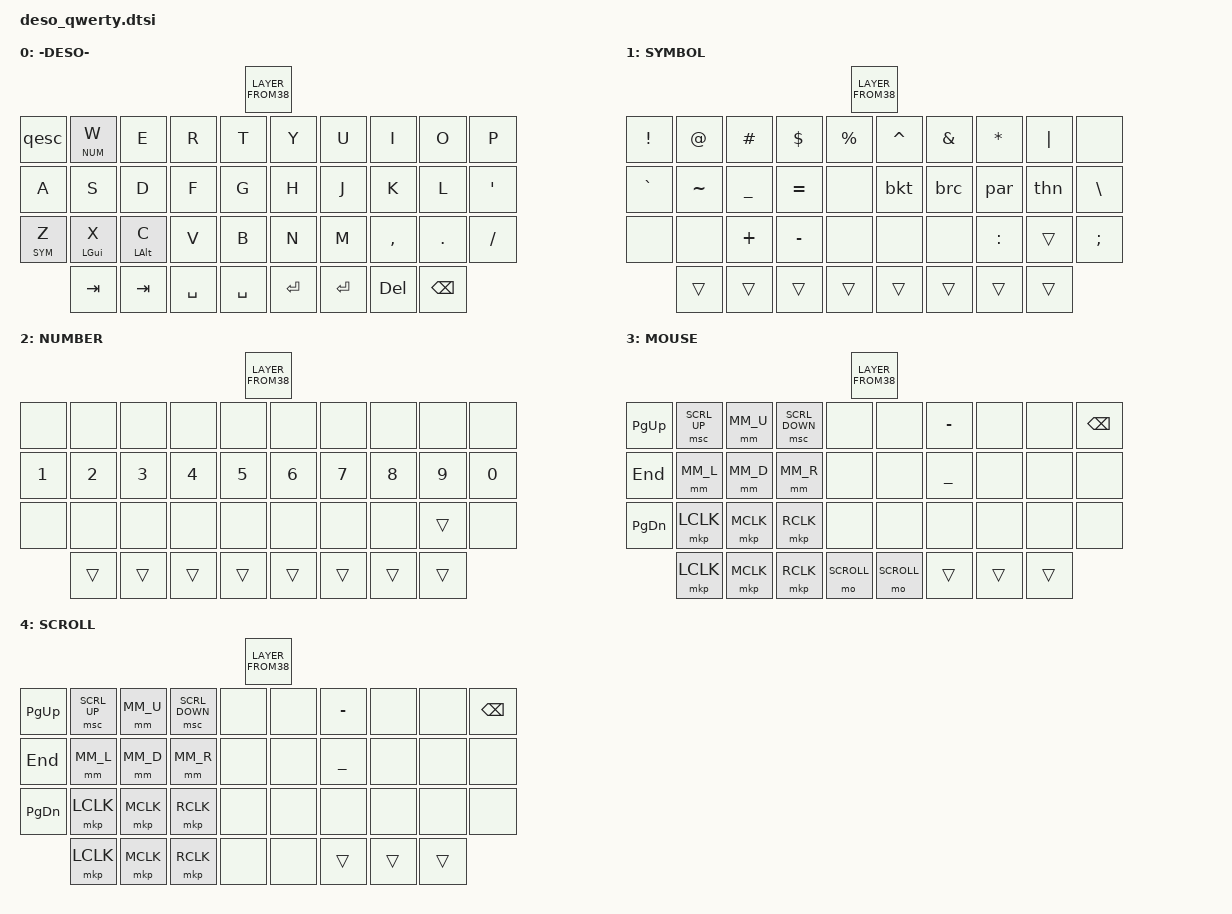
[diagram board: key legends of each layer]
/*
 * Last Update 10/5/24
 * QWERTY 19x2
 * 
 */

#include <behaviors.dtsi>
#include <input/processors.dtsi>
#include <dt-bindings/zmk/keys.h>
#include <dt-bindings/zmk/bt.h>
#include <dt-bindings/zmk/outputs.h>
#include <dt-bindings/zmk/mouse.h>
#include <dt-bindings/zmk/input_transform.h>
#include <zephyr/dt-bindings/input/input-event-codes.h>


#define DEFAULT     0
#define SYMBOL      1
#define NUMBER      2
#define MOUSE       3 
#define SCROLL      4

&mt {
    flavor = "tap-preferred";
    tapping_term_ms = <180>;
};

&lt {
    tapping_term_ms = <150>;
};

/ {
    combos {

        compatible = "zmk,combos";
        combo_bootloader {
            timeout-ms = <50>;
            key-positions = <1 10>;
            bindings = <&bootloader>;
        };
    };

    behaviors {

        qesc: tap_dance_qesc {
            compatible = "zmk,behavior-tap-dance";
            #binding-cells = <0>;
            tapping-term-ms = <300>;
            bindings = <&kp Q>, <&kp ESC>;
        };

        bkt: tap_dance_bracket {
            compatible = "zmk,behavior-tap-dance";
            #binding-cells = <0>;
            tapping-term-ms = <200>;
            bindings = <&kp LBKT>, <&kp RBKT>;
        };

        brc: tap_dance_brace {
            compatible = "zmk,behavior-tap-dance";
            #binding-cells = <0>;
            tapping-term-ms = <200>;
            bindings = <&kp LBRC>, <&kp RBRC>;
        };

        par: tap_dance_paren {
            compatible = "zmk,behavior-tap-dance";
            #binding-cells = <0>;
            tapping-term-ms = <200>;
            bindings = <&kp LPAR>, <&kp RPAR>;
        };

        thn: tap_dance_then {
            compatible = "zmk,behavior-tap-dance";
            #binding-cells = <0>;
            tapping-term-ms = <200>;
            bindings = <&kp LT>, <&kp GT>;
        };

        hrm: homerow_mods {
           compatible = "zmk,behavior-hold-tap";
           #binding-cells = <2>;
           tapping-term-ms = <250>;
           quick-tap-ms = <0>;
           flavor = "tap-preferred";
           bindings = <&kp>, <&kp>;
        };

        // keys to a fake mouse input device
        mm: mouse_move {
            compatible = "zmk,behavior-input-two-axis";
            #binding-cells = <1>;
            trigger-period-ms = <12>;
            x-input-code = <INPUT_REL_X>;
            y-input-code = <INPUT_REL_Y>;
            time-to-max-speed-ms = <10>;
            acceleration-exponent = <1>;
        };

    };


#ifndef MOVE_Y
#define MOVE_Y(n) (0)
#endif
#ifndef MOVE_X
#define MOVE_X(n) (0)
#endif

#define U_MOUSE_MOVE_MAX 1700
#define MM_U MOVE_Y(-U_MOUSE_MOVE_MAX)
#define MM_D MOVE_Y(U_MOUSE_MOVE_MAX)
#define MM_L MOVE_X(-U_MOUSE_MOVE_MAX)
#define MM_R MOVE_X(U_MOUSE_MOVE_MAX)

 
    to_wheel: to_wheel {
        compatible = "zmk,input-processor-code-mapper";
        #input-processor-cells = <0>;
        type = <INPUT_EV_REL>;
        map = <INPUT_REL_X INPUT_REL_HWHEEL>
            , <INPUT_REL_Y INPUT_REL_WHEEL>;
    };

    trackball_listener {
        input-processors = <&zip_temp_layer MOUSE 1200>;

        scroll {
            layers = <SCROLL>;
            input-processors = <&zip_xy_scaler 1 18>, <&to_wheel>, <&zip_scroll_transform (INPUT_TRANSFORM_Y_INVERT)>;
        };
    };


    // mapping the fake keys to mouse device tack to the layers
    mmv_input_listener {
        compatible = "zmk,input-listener";
        device = <&mm>;
        input-processors = <&zip_xy_scaler 1 1>, <&zip_temp_layer MOUSE 1200>;

        scroll {
            inherit;
            layers = <MOUSE>;
            input-processors = <&zip_xy_scaler 1 7>, <&to_wheel>, <&zip_scroll_transform (INPUT_TRANSFORM_Y_INVERT)>;
        };
    };


    keymap {
        compatible = "zmk,keymap";

        default_layer {
            display-name = "-DESO-";  
            bindings = <LAYER_FROM38( \
                &qesc, &lt NUM W, &kp E, &kp R, &kp T, &kp Y, &kp U, &kp I, &kp O, &kp P, \
                &kp A, &kp S, &kp D, &kp F, &kp G, &kp H, &kp J, &kp K, &kp L, &kp SQT,   \
                &lt SYM Z, &hrm LGUI X, &hrm LALT C, &kp V, &kp B, &kp N, &kp M, &kp COMMA, &kp DOT, &kp SLASH, \
                &kp TAB, &kp TAB, &kp SPACE, &kp SPACE, &kp RET, &kp RET, &kp DEL, &kp BSPC \
            )>;
        };

        symbol_layer {
            display-name = "SYMBOL";  
            bindings = <LAYER_FROM38( \
                &kp EXCL, &kp AT, &kp HASH, &kp DLLR, &kp PRCNT, &kp CARET, &kp AMPS, &kp STAR, &kp PIPE, &none, \
                &kp GRAVE, &kp TILDE, &kp UNDER, &kp EQUAL, &none, &bkt, &brc, &par, &thn, &kp BSLH, \
                &none, &none, &kp PLUS, &kp MINUS, &none, &none, &none, &kp COLON, &trans, &kp SEMI, \
                &trans, &trans, &trans, &trans, &trans, &trans, &trans, &trans \
            )>;
        };

        number_layer {
            display-name = "NUMBER";  
            bindings = <LAYER_FROM38( \
                &none, &none, &none, &none, &none, &none, &none, &none, &none, &none, \
                &kp N1, &kp N2, &kp N3, &kp N4, &kp N5, &kp N6, &kp N7, &kp N8, &kp N9, &kp N0, \
                &none, &none, &none, &none, &none, &none, &none, &none, &trans, &none, \
                &trans, &trans, &trans, &trans, &trans, &trans, &trans, &trans \
            )>;
        };

        mouse_layer {
            display-name = "MOUSE";  
            bindings = <LAYER_FROM38( \
                &kp PG_UP, &msc SCRL_UP, &mm MM_U, &msc SCRL_DOWN, &none, &none, &kp MINUS, &none, &none, &kp BSPC, \
                &kp END, &mm MM_L, &mm MM_D, &mm MM_R, &none, &none, &kp UNDER, &none, &none, &none, \
                &kp PG_DN, &mkp LCLK, &mkp MCLK, &mkp RCLK, &none, &none, &none, &none, &none, &none, \
                &mkp LCLK, &mkp MCLK, &mkp RCLK, &mo SCROLL, &mo SCROLL, &trans, &trans, &trans \
            )>;
        };

        scroll_layer {
            display-name = "SCROLL";  
            bindings = <LAYER_FROM38( \
                &kp PG_UP, &msc SCRL_UP, &mm MM_U, &msc SCRL_DOWN, &none, &none, &kp MINUS, &none, &none, &kp BSPC, \
                &kp END, &mm MM_L, &mm MM_D, &mm MM_R, &none, &none, &kp UNDER, &none, &none, &none, \
                &kp PG_DN, &mkp LCLK, &mkp MCLK, &mkp RCLK, &none, &none, &none, &none, &none, &none, \
                &mkp LCLK, &mkp MCLK, &mkp RCLK, &none, &none, &trans, &trans, &trans \
            )>;
        };

    };
};
